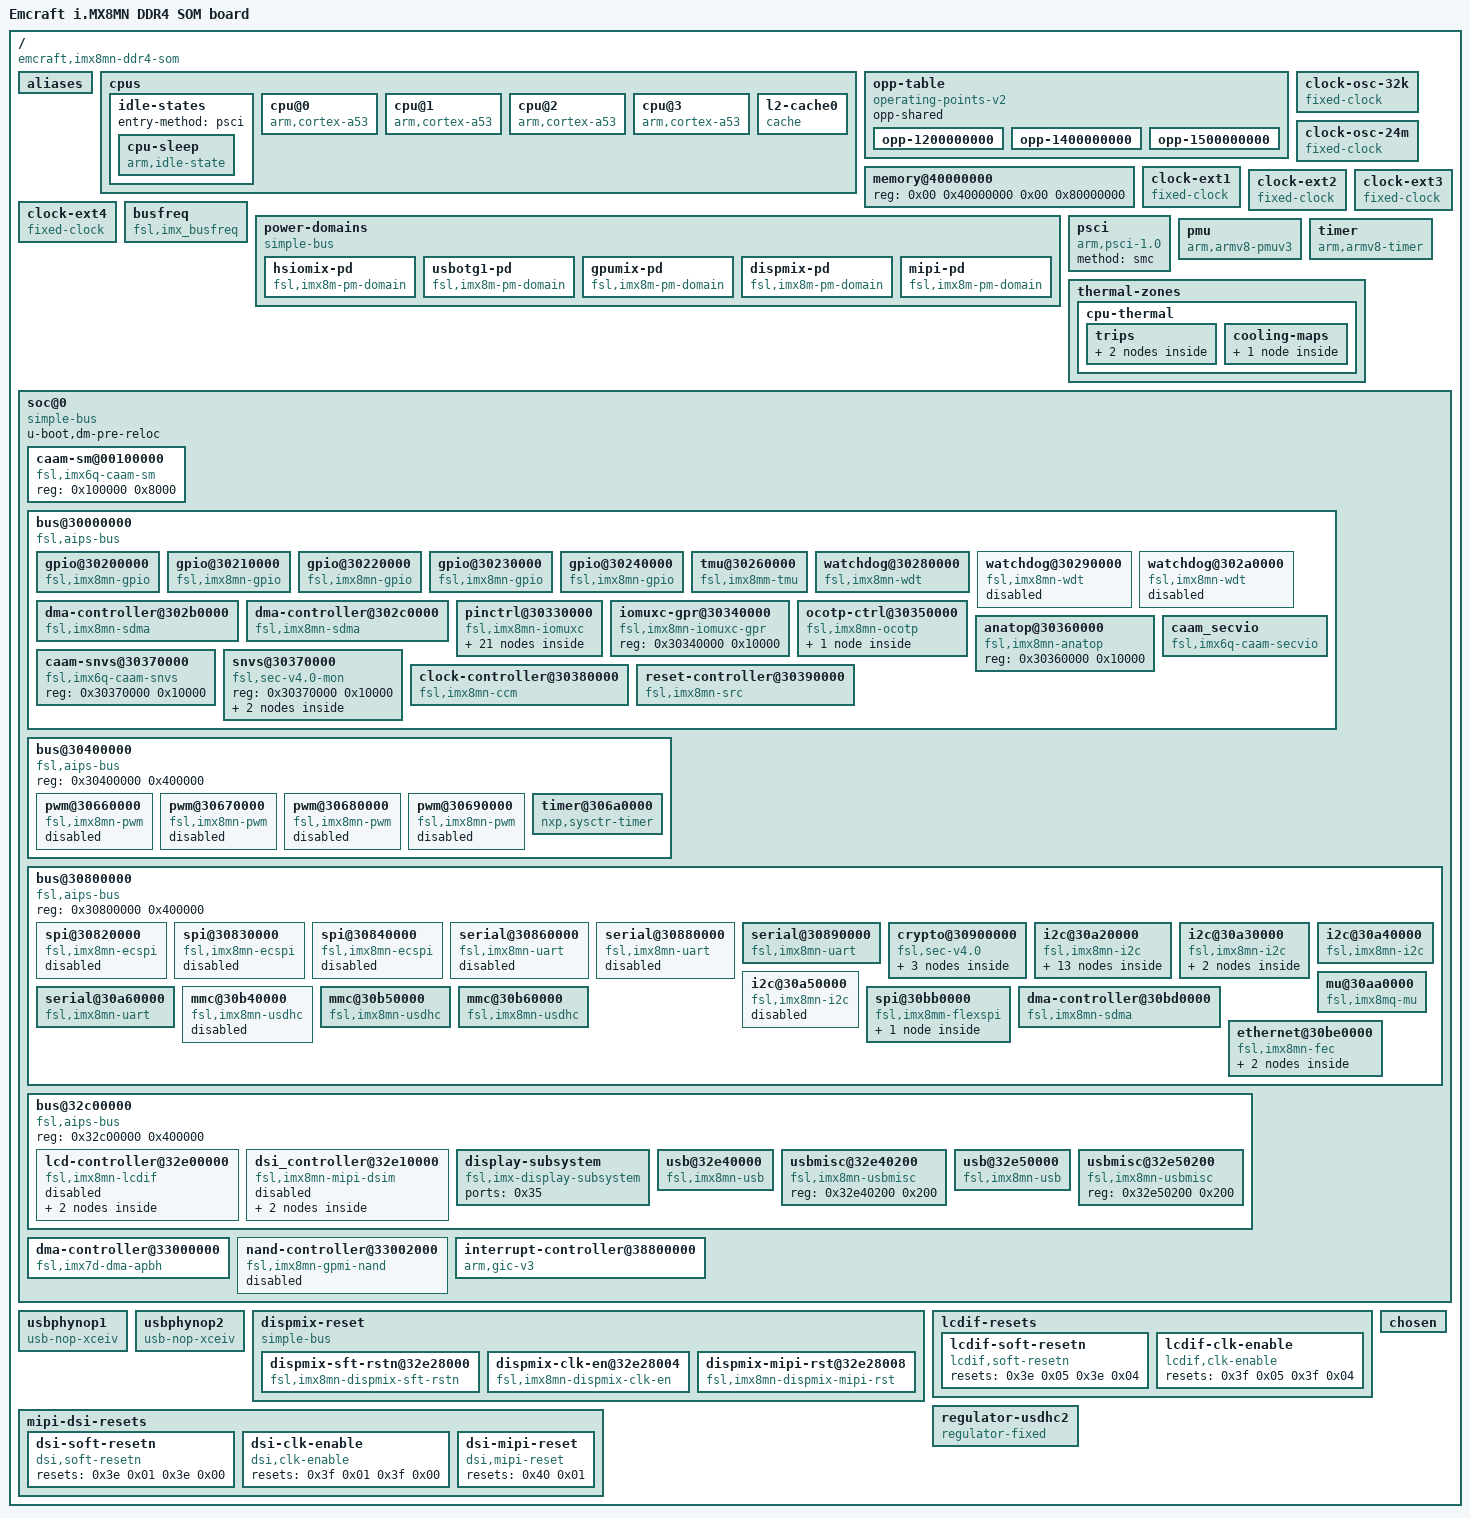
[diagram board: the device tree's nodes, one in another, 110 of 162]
/dts-v1/;

/ {
	compatible = "emcraft,imx8mn-ddr4-som\0fsl,imx8mn";
	interrupt-parent = <0x01>;
	#address-cells = <0x02>;
	#size-cells = <0x02>;
	model = "Emcraft i.MX8MN DDR4 SOM board";

	aliases {
		ethernet0 = "/soc@0/bus@30800000/ethernet@30be0000";
		gpio0 = "/soc@0/bus@30000000/gpio@30200000";
		gpio1 = "/soc@0/bus@30000000/gpio@30210000";
		gpio2 = "/soc@0/bus@30000000/gpio@30220000";
		gpio3 = "/soc@0/bus@30000000/gpio@30230000";
		gpio4 = "/soc@0/bus@30000000/gpio@30240000";
		i2c0 = "/soc@0/bus@30800000/i2c@30a20000";
		i2c1 = "/soc@0/bus@30800000/i2c@30a30000";
		i2c2 = "/soc@0/bus@30800000/i2c@30a40000";
		i2c3 = "/soc@0/bus@30800000/i2c@30a50000";
		mmc0 = "/soc@0/bus@30800000/mmc@30b40000";
		mmc1 = "/soc@0/bus@30800000/mmc@30b50000";
		mmc2 = "/soc@0/bus@30800000/mmc@30b60000";
		serial0 = "/soc@0/bus@30800000/serial@30860000";
		serial1 = "/soc@0/bus@30800000/serial@30890000";
		serial2 = "/soc@0/bus@30800000/serial@30880000";
		serial3 = "/soc@0/bus@30800000/serial@30a60000";
		spi0 = "/soc@0/bus@30800000/spi@30bb0000";
		usb0 = "/soc@0/bus@32c00000/usb@32e40000";
		usb1 = "/soc@0/bus@32c00000/usb@32e50000";
		video0 = "/soc@0/bus@32c00000/lcd-controller@32e00000";
	};

	cpus {
		#address-cells = <0x01>;
		#size-cells = <0x00>;

		idle-states {
			entry-method = "psci";

			cpu-sleep {
				compatible = "arm,idle-state";
				arm,psci-suspend-param = <0x10033>;
				local-timer-stop;
				entry-latency-us = <0x3e8>;
				exit-latency-us = <0x2bc>;
				min-residency-us = <0xa8c>;
				wakeup-latency-us = <0x5dc>;
				phandle = <0x06>;
			};
		};

		cpu@0 {
			device_type = "cpu";
			compatible = "arm,cortex-a53";
			reg = <0x00>;
			clock-latency = <0xee6c>;
			clocks = <0x02 0xbf>;
			enable-method = "psci";
			next-level-cache = <0x03>;
			operating-points-v2 = <0x04>;
			nvmem-cells = <0x05>;
			nvmem-cell-names = "speed_grade";
			cpu-idle-states = <0x06>;
			#cooling-cells = <0x02>;
			phandle = <0x09>;
		};

		cpu@1 {
			device_type = "cpu";
			compatible = "arm,cortex-a53";
			reg = <0x01>;
			clock-latency = <0xee6c>;
			clocks = <0x02 0xbf>;
			enable-method = "psci";
			next-level-cache = <0x03>;
			operating-points-v2 = <0x04>;
			cpu-idle-states = <0x06>;
			#cooling-cells = <0x02>;
			phandle = <0x0a>;
		};

		cpu@2 {
			device_type = "cpu";
			compatible = "arm,cortex-a53";
			reg = <0x02>;
			clock-latency = <0xee6c>;
			clocks = <0x02 0xbf>;
			enable-method = "psci";
			next-level-cache = <0x03>;
			operating-points-v2 = <0x04>;
			cpu-idle-states = <0x06>;
			#cooling-cells = <0x02>;
			phandle = <0x0b>;
		};

		cpu@3 {
			device_type = "cpu";
			compatible = "arm,cortex-a53";
			reg = <0x03>;
			clock-latency = <0xee6c>;
			clocks = <0x02 0xbf>;
			enable-method = "psci";
			next-level-cache = <0x03>;
			operating-points-v2 = <0x04>;
			cpu-idle-states = <0x06>;
			#cooling-cells = <0x02>;
			phandle = <0x0c>;
		};

		l2-cache0 {
			compatible = "cache";
			phandle = <0x03>;
		};
	};

	opp-table {
		compatible = "operating-points-v2";
		opp-shared;
		phandle = <0x04>;

		opp-1200000000 {
			opp-hz = <0x00 0x47868c00>;
			opp-microvolt = <0xcf850>;
			opp-supported-hw = <0xb00 0x07>;
			clock-latency-ns = <0x249f0>;
			opp-suspend;
		};

		opp-1400000000 {
			opp-hz = <0x00 0x53724e00>;
			opp-microvolt = <0xe7ef0>;
			opp-supported-hw = <0x300 0x07>;
			clock-latency-ns = <0x249f0>;
			opp-suspend;
		};

		opp-1500000000 {
			opp-hz = <0x00 0x59682f00>;
			opp-microvolt = <0xf4240>;
			opp-supported-hw = <0x100 0x03>;
			clock-latency-ns = <0x249f0>;
			opp-suspend;
		};
	};

	memory@40000000 {
		device_type = "memory";
		reg = <0x00 0x40000000 0x00 0x80000000>;
	};

	clock-osc-32k {
		compatible = "fixed-clock";
		#clock-cells = <0x00>;
		clock-frequency = <0x8000>;
		clock-output-names = "osc_32k";
		phandle = <0x13>;
	};

	clock-osc-24m {
		compatible = "fixed-clock";
		#clock-cells = <0x00>;
		clock-frequency = <0x16e3600>;
		clock-output-names = "osc_24m";
		phandle = <0x14>;
	};

	clock-ext1 {
		compatible = "fixed-clock";
		#clock-cells = <0x00>;
		clock-frequency = <0x7ed6b40>;
		clock-output-names = "clk_ext1";
		phandle = <0x15>;
	};

	clock-ext2 {
		compatible = "fixed-clock";
		#clock-cells = <0x00>;
		clock-frequency = <0x7ed6b40>;
		clock-output-names = "clk_ext2";
		phandle = <0x16>;
	};

	clock-ext3 {
		compatible = "fixed-clock";
		#clock-cells = <0x00>;
		clock-frequency = <0x7ed6b40>;
		clock-output-names = "clk_ext3";
		phandle = <0x17>;
	};

	clock-ext4 {
		compatible = "fixed-clock";
		#clock-cells = <0x00>;
		clock-frequency = <0x7ed6b40>;
		clock-output-names = "clk_ext4";
		phandle = <0x18>;
	};

	busfreq {
		compatible = "fsl,imx_busfreq";
		clocks = <0x02 0x29 0x02 0x59 0x02 0x5a 0x02 0x5a 0x02 0x58 0x02 0x5b 0x02 0x30 0x02 0x32 0x02 0x3f 0x02 0x53 0x02 0x54 0x02 0x4b 0x02 0x02 0x02 0x38 0x02 0x15>;
		clock-names = "dram_pll\0dram_alt_src\0dram_apb_src\0dram_apb_pre_div\0dram_core\0dram_alt_root\0sys_pll1_40m\0sys_pll1_100m\0sys_pll2_333m\0noc_div\0ahb_div\0main_axi_src\0osc_24m\0sys_pll1_800m\0dram_pll_div";
	};

	power-domains {
		compatible = "simple-bus";

		hsiomix-pd {
			compatible = "fsl,imx8m-pm-domain";
			domain-index = <0x00>;
			#power-domain-cells = <0x00>;
			domain-name = "hsiomix";
			clocks = <0x02 0xad>;
			phandle = <0x07>;
		};

		usbotg1-pd {
			compatible = "fsl,imx8m-pm-domain";
			#power-domain-cells = <0x00>;
			domain-index = <0x02>;
			domain-name = "usb_otg1";
			parent-domains = <0x07>;
			phandle = <0x38>;
		};

		gpumix-pd {
			compatible = "fsl,imx8m-pm-domain";
			domain-index = <0x04>;
			#power-domain-cells = <0x00>;
			domain-name = "gpumix";
			clocks = <0x02 0xc1 0x02 0x4a 0x02 0xb3 0x02 0x52>;
		};

		dispmix-pd {
			compatible = "fsl,imx8m-pm-domain";
			domain-index = <0x09>;
			#power-domain-cells = <0x00>;
			domain-name = "dispmix";
			clocks = <0x02 0xb8 0x02 0xb9>;
			phandle = <0x08>;
		};

		mipi-pd {
			compatible = "fsl,imx8m-pm-domain";
			domain-index = <0x0a>;
			#power-domain-cells = <0x00>;
			domain-name = "mipi";
			parent-domains = <0x08>;
			phandle = <0x33>;
		};
	};

	psci {
		compatible = "arm,psci-1.0";
		method = "smc";
	};

	pmu {
		compatible = "arm,armv8-pmuv3";
		interrupts = <0x01 0x07 0x3f04>;
		interrupt-affinity = <0x09 0x0a 0x0b 0x0c>;
	};

	timer {
		compatible = "arm,armv8-timer";
		interrupts = <0x01 0x0d 0x3f08 0x01 0x0e 0x3f08 0x01 0x0b 0x3f08 0x01 0x0a 0x3f08>;
		clock-frequency = <0x7a1200>;
		arm,no-tick-in-suspend;
	};

	thermal-zones {

		cpu-thermal {
			polling-delay-passive = <0xfa>;
			polling-delay = <0x7d0>;
			thermal-sensors = <0x0d>;

			trips {

				trip0 {
					temperature = <0x14c08>;
					hysteresis = <0x7d0>;
					type = "passive";
					phandle = <0x0e>;
				};

				trip1 {
					temperature = <0x17318>;
					hysteresis = <0x7d0>;
					type = "critical";
				};
			};

			cooling-maps {

				map0 {
					trip = <0x0e>;
					cooling-device = <0x09 0xffffffff 0xffffffff 0x0a 0xffffffff 0xffffffff 0x0b 0xffffffff 0xffffffff 0x0c 0xffffffff 0xffffffff>;
				};
			};
		};
	};

	soc@0 {
		compatible = "simple-bus";
		#address-cells = <0x01>;
		#size-cells = <0x01>;
		ranges = <0x00 0x00 0x00 0x3e000000>;
		u-boot,dm-pre-reloc;

		caam-sm@00100000 {
			compatible = "fsl,imx6q-caam-sm";
			reg = <0x100000 0x8000>;
		};

		bus@30000000 {
			compatible = "fsl,aips-bus\0simple-bus";
			reg = <0x30000000 0x400000>;
			#address-cells = <0x01>;
			#size-cells = <0x01>;
			ranges;
			u-boot,dm-pre-reloc;

			gpio@30200000 {
				compatible = "fsl,imx8mn-gpio\0fsl,imx35-gpio";
				reg = <0x30200000 0x10000>;
				interrupts = <0x00 0x40 0x04 0x00 0x41 0x04>;
				clocks = <0x02 0x8c>;
				gpio-controller;
				#gpio-cells = <0x02>;
				interrupt-controller;
				#interrupt-cells = <0x02>;
				gpio-ranges = <0x0f 0x00 0x0a 0x1e>;
				u-boot,dm-pre-reloc;
				phandle = <0x1f>;
			};

			gpio@30210000 {
				compatible = "fsl,imx8mn-gpio\0fsl,imx35-gpio";
				reg = <0x30210000 0x10000>;
				interrupts = <0x00 0x42 0x04 0x00 0x43 0x04>;
				clocks = <0x02 0x8d>;
				gpio-controller;
				#gpio-cells = <0x02>;
				interrupt-controller;
				#interrupt-cells = <0x02>;
				gpio-ranges = <0x0f 0x00 0x28 0x15>;
				u-boot,dm-pre-reloc;
				phandle = <0x42>;
			};

			gpio@30220000 {
				compatible = "fsl,imx8mn-gpio\0fsl,imx35-gpio";
				reg = <0x30220000 0x10000>;
				interrupts = <0x00 0x44 0x04 0x00 0x45 0x04>;
				clocks = <0x02 0x8e>;
				gpio-controller;
				#gpio-cells = <0x02>;
				interrupt-controller;
				#interrupt-cells = <0x02>;
				gpio-ranges = <0x0f 0x00 0x3d 0x1a>;
				u-boot,dm-pre-reloc;
			};

			gpio@30230000 {
				compatible = "fsl,imx8mn-gpio\0fsl,imx35-gpio";
				reg = <0x30230000 0x10000>;
				interrupts = <0x00 0x46 0x04 0x00 0x47 0x04>;
				clocks = <0x02 0x8f>;
				gpio-controller;
				#gpio-cells = <0x02>;
				interrupt-controller;
				#interrupt-cells = <0x02>;
				gpio-ranges = <0x0f 0x15 0x6c 0x0b>;
				u-boot,dm-pre-reloc;
			};

			gpio@30240000 {
				compatible = "fsl,imx8mn-gpio\0fsl,imx35-gpio";
				reg = <0x30240000 0x10000>;
				interrupts = <0x00 0x48 0x04 0x00 0x49 0x04>;
				clocks = <0x02 0x90>;
				gpio-controller;
				#gpio-cells = <0x02>;
				interrupt-controller;
				#interrupt-cells = <0x02>;
				gpio-ranges = <0x0f 0x00 0x77 0x1e>;
				u-boot,dm-pre-reloc;
				phandle = <0x1d>;
			};

			tmu@30260000 {
				compatible = "fsl,imx8mm-tmu";
				reg = <0x30260000 0x10000>;
				clocks = <0x02 0xbe>;
				u-boot,dm-pre-reloc;
				#thermal-sensor-cells = <0x00>;
				phandle = <0x0d>;
			};

			watchdog@30280000 {
				compatible = "fsl,imx8mn-wdt\0fsl,imx21-wdt";
				reg = <0x30280000 0x10000>;
				interrupts = <0x00 0x4e 0x04>;
				clocks = <0x02 0xb0>;
				status = "okay";
				pinctrl-names = "default";
				pinctrl-0 = <0x10>;
				fsl,ext-reset-output;
			};

			watchdog@30290000 {
				compatible = "fsl,imx8mn-wdt\0fsl,imx21-wdt";
				reg = <0x30290000 0x10000>;
				interrupts = <0x00 0x4f 0x04>;
				clocks = <0x02 0xb1>;
				status = "disabled";
			};

			watchdog@302a0000 {
				compatible = "fsl,imx8mn-wdt\0fsl,imx21-wdt";
				reg = <0x302a0000 0x10000>;
				interrupts = <0x00 0x0a 0x04>;
				clocks = <0x02 0xb2>;
				status = "disabled";
			};

			dma-controller@302b0000 {
				compatible = "fsl,imx8mn-sdma\0fsl,imx8mq-sdma\0fsl,imx7d-sdma";
				reg = <0x302b0000 0x10000>;
				interrupts = <0x00 0x22 0x04>;
				clocks = <0x02 0xbd 0x02 0xbd>;
				clock-names = "ipg\0ahb";
				#dma-cells = <0x03>;
				fsl,sdma-ram-script-name = "imx/sdma/sdma-imx7d.bin";
			};

			dma-controller@302c0000 {
				compatible = "fsl,imx8mn-sdma\0fsl,imx8mq-sdma\0fsl,imx7d-sdma";
				reg = <0x302c0000 0x10000>;
				interrupts = <0x00 0x67 0x04>;
				clocks = <0x02 0xa8 0x02 0xa8>;
				clock-names = "ipg\0ahb";
				#dma-cells = <0x03>;
				fsl,sdma-ram-script-name = "imx/sdma/sdma-imx7d.bin";
			};

			pinctrl@30330000 {
				compatible = "fsl,imx8mn-iomuxc";
				reg = <0x30330000 0x10000>;
				pinctrl-names = "default";
				pinctrl-0 = <0x11>;
				phandle = <0x0f>;

				imx8mn-evk {

					hoggrp-1 {
						fsl,pins = <0x48 0x2b0 0x00 0x00 0x00 0x16>;
						phandle = <0x11>;
					};

					fec1grp {
						fsl,pins = <0x68 0x2d0 0x00 0x00 0x00 0x03 0x6c 0x2d4 0x4c0 0x00 0x01 0x03 0x70 0x2d8 0x00 0x00 0x00 0x1f 0x74 0x2dc 0x00 0x00 0x00 0x1f 0x78 0x2e0 0x00 0x00 0x00 0x1f 0x7c 0x2e4 0x00 0x00 0x00 0x1f 0x9c 0x304 0x00 0x00 0x00 0x91 0x98 0x300 0x00 0x00 0x00 0x91 0x94 0x2fc 0x554 0x00 0x00 0x91 0x90 0x2f8 0x57c 0x00 0x00 0x91 0x84 0x2ec 0x00 0x00 0x00 0x1f 0x8c 0x2f4 0x00 0x00 0x00 0x91 0x88 0x2f0 0x574 0x00 0x00 0x91 0x80 0x2e8 0x00 0x00 0x00 0x1f 0x1b4 0x41c 0x00 0x05 0x00 0x19>;
						phandle = <0x2e>;
					};

					flexspi0grp {
						fsl,pins = <0xf4 0x35c 0x00 0x01 0x00 0x1c4 0xf8 0x360 0x00 0x01 0x00 0x84 0x10c 0x374 0x00 0x01 0x00 0x84 0x110 0x378 0x00 0x01 0x00 0x84 0x114 0x37c 0x00 0x01 0x00 0x84 0x118 0x380 0x00 0x01 0x00 0x84>;
						phandle = <0x2c>;
					};

					i2c1grp {
						fsl,pins = <0x214 0x47c 0x55c 0x00 0x00 0x400001c3 0x218 0x480 0x56c 0x00 0x00 0x400001c3>;
						phandle = <0x1b>;
					};

					i2c2grp {
						fsl,pins = <0x21c 0x484 0x5d0 0x00 0x00 0x400001c3 0x220 0x488 0x560 0x00 0x00 0x400001c3>;
						phandle = <0x20>;
					};

					i2c3grp {
						fsl,pins = <0x224 0x48c 0x588 0x00 0x00 0x400001c3 0x228 0x490 0x5bc 0x00 0x00 0x400001c3>;
						phandle = <0x22>;
					};

					i2c1grp-gpio {
						fsl,pins = <0x214 0x47c 0x00 0x05 0x00 0x1c3 0x218 0x480 0x00 0x05 0x00 0x1c3>;
						phandle = <0x1c>;
					};

					i2c2grp-gpio {
						fsl,pins = <0x21c 0x484 0x00 0x05 0x00 0x1c3 0x220 0x488 0x00 0x05 0x00 0x1c3>;
						phandle = <0x21>;
					};

					i2c3grp-gpio {
						fsl,pins = <0x224 0x48c 0x00 0x05 0x00 0x1c3 0x228 0x490 0x00 0x05 0x00 0x1c3>;
						phandle = <0x23>;
					};

					pmicirq {
						fsl,pins = <0x34 0x29c 0x00 0x00 0x00 0x41>;
						phandle = <0x1e>;
					};

					regusdhc2vmmc {
						fsl,pins = <0xec 0x354 0x00 0x05 0x00 0x41>;
						phandle = <0x41>;
					};

					uart2grp {
						fsl,pins = <0x23c 0x4a4 0x4fc 0x00 0x00 0x144 0x240 0x4a8 0x00 0x00 0x00 0x144>;
						phandle = <0x1a>;
					};

					usdhc2grpgpio {
						fsl,pins = <0x64 0x2cc 0x00 0x00 0x00 0x1c4>;
						phandle = <0x25>;
					};

					usdhc2grp {
						fsl,pins = <0xd4 0x33c 0x00 0x00 0x00 0x190 0xd8 0x340 0x00 0x00 0x00 0x1d0 0xdc 0x344 0x00 0x00 0x00 0x1d0 0xe0 0x348 0x00 0x00 0x00 0x1d0 0xe4 0x34c 0x00 0x00 0x00 0x1d0 0xe8 0x350 0x00 0x00 0x00 0x1d0 0x38 0x2a0 0x00 0x01 0x00 0x1d0>;
						phandle = <0x24>;
					};

					usdhc2grp100mhz {
						fsl,pins = <0xd4 0x33c 0x00 0x00 0x00 0x194 0xd8 0x340 0x00 0x00 0x00 0x1d4 0xdc 0x344 0x00 0x00 0x00 0x1d4 0xe0 0x348 0x00 0x00 0x00 0x1d4 0xe4 0x34c 0x00 0x00 0x00 0x1d4 0xe8 0x350 0x00 0x00 0x00 0x1d4 0x38 0x2a0 0x00 0x01 0x00 0x1d0>;
						phandle = <0x26>;
					};

					usdhc2grp200mhz {
						fsl,pins = <0xd4 0x33c 0x00 0x00 0x00 0x196 0xd8 0x340 0x00 0x00 0x00 0x1d6 0xdc 0x344 0x00 0x00 0x00 0x1d6 0xe0 0x348 0x00 0x00 0x00 0x1d6 0xe4 0x34c 0x00 0x00 0x00 0x1d6 0xe8 0x350 0x00 0x00 0x00 0x1d6 0x38 0x2a0 0x00 0x01 0x00 0x1d0>;
						phandle = <0x27>;
					};

					usdhc3grp {
						fsl,pins = <0x138 0x3a0 0x5a0 0x02 0x00 0x40000190 0x13c 0x3a4 0x5dc 0x02 0x00 0x1d0 0x11c 0x384 0x5b4 0x02 0x00 0x1d0 0x120 0x388 0x5b0 0x02 0x00 0x1d0 0x124 0x38c 0x5e4 0x02 0x00 0x1d0 0x128 0x390 0x5e0 0x02 0x00 0x1d0 0x130 0x398 0x558 0x02 0x00 0x1d0 0x100 0x368 0x550 0x02 0x00 0x1d0 0x104 0x36c 0x584 0x02 0x00 0x1d0 0x108 0x370 0x54c 0x02 0x00 0x1d0 0xfc 0x364 0x59c 0x02 0x00 0x190>;
						phandle = <0x29>;
					};

					usdhc3grp100mhz {
						fsl,pins = <0x138 0x3a0 0x5a0 0x02 0x00 0x40000194 0x13c 0x3a4 0x5dc 0x02 0x00 0x1d4 0x11c 0x384 0x5b4 0x02 0x00 0x1d4 0x120 0x388 0x5b0 0x02 0x00 0x1d4 0x124 0x38c 0x5e4 0x02 0x00 0x1d4 0x128 0x390 0x5e0 0x02 0x00 0x1d4 0x130 0x398 0x558 0x02 0x00 0x1d4 0x100 0x368 0x550 0x02 0x00 0x1d4 0x104 0x36c 0x584 0x02 0x00 0x1d4 0x108 0x370 0x54c 0x02 0x00 0x1d4 0xfc 0x364 0x59c 0x02 0x00 0x194>;
						phandle = <0x2a>;
					};

					usdhc3grp200mhz {
						fsl,pins = <0x138 0x3a0 0x5a0 0x02 0x00 0x40000196 0x13c 0x3a4 0x5dc 0x02 0x00 0x1d6 0x11c 0x384 0x5b4 0x02 0x00 0x1d6 0x120 0x388 0x5b0 0x02 0x00 0x1d6 0x124 0x38c 0x5e4 0x02 0x00 0x1d6 0x128 0x390 0x5e0 0x02 0x00 0x1d6 0x130 0x398 0x558 0x02 0x00 0x1d6 0x100 0x368 0x550 0x02 0x00 0x1d6 0x104 0x36c 0x584 0x02 0x00 0x1d6 0x108 0x370 0x54c 0x02 0x00 0x1d6 0xfc 0x364 0x59c 0x02 0x00 0x196>;
						phandle = <0x2b>;
					};

					wdoggrp {
						fsl,pins = <0x30 0x298 0x00 0x01 0x00 0xc6>;
						phandle = <0x10>;
					};
				};
			};

			iomuxc-gpr@30340000 {
				compatible = "fsl,imx8mn-iomuxc-gpr\0syscon";
				reg = <0x30340000 0x10000>;
				phandle = <0x2d>;
			};

			ocotp-ctrl@30350000 {
				compatible = "fsl,imx8mn-ocotp\0fsl,imx7d-ocotp\0syscon";
				reg = <0x30350000 0x10000>;
				clocks = <0x02 0x96>;
				#address-cells = <0x01>;
				#size-cells = <0x01>;

				speed-grade@10 {
					reg = <0x10 0x04>;
					phandle = <0x05>;
				};
			};

			anatop@30360000 {
				compatible = "fsl,imx8mn-anatop\0fsl,imx8mm-anatop\0syscon\0simple-bus";
				reg = <0x30360000 0x10000>;
			};

			caam_secvio {
				compatible = "fsl,imx6q-caam-secvio";
				interrupts = <0x00 0x14 0x04>;
				jtag-tamper = "disabled";
				watchdog-tamper = "enabled";
				internal-boot-tamper = "enabled";
				external-pin-tamper = "disabled";
			};

			caam-snvs@30370000 {
				compatible = "fsl,imx6q-caam-snvs";
				reg = <0x30370000 0x10000>;
			};

			snvs@30370000 {
				compatible = "fsl,sec-v4.0-mon\0syscon\0simple-mfd";
				reg = <0x30370000 0x10000>;
				phandle = <0x12>;

				snvs-rtc-lp {
					compatible = "fsl,sec-v4.0-mon-rtc-lp";
					regmap = <0x12>;
					offset = <0x34>;
					interrupts = <0x00 0x13 0x04 0x00 0x14 0x04>;
					clocks = <0x02 0xc4>;
					clock-names = "snvs-rtc";
				};

				snvs-powerkey {
					compatible = "fsl,sec-v4.0-pwrkey";
					regmap = <0x12>;
					interrupts = <0x00 0x04 0x04>;
					linux,keycode = <0x74>;
					wakeup-source;
					status = "okay";
				};
			};

			clock-controller@30380000 {
				compatible = "fsl,imx8mn-ccm";
				reg = <0x30380000 0x10000>;
				#clock-cells = <0x01>;
				clocks = <0x13 0x14 0x15 0x16 0x17 0x18>;
				clock-names = "osc_32k\0osc_24m\0clk_ext1\0clk_ext2\0clk_ext3\0clk_ext4";
				phandle = <0x02>;
			};

			reset-controller@30390000 {
				compatible = "fsl,imx8mn-src\0syscon";
				reg = <0x30390000 0x10000>;
				interrupts = <0x00 0x59 0x04>;
				#reset-cells = <0x01>;
			};
		};

		bus@30400000 {
			compatible = "fsl,aips-bus\0simple-bus";
			reg = <0x30400000 0x400000>;
			#address-cells = <0x01>;
			#size-cells = <0x01>;
			ranges;

			pwm@30660000 {
				compatible = "fsl,imx8mn-pwm\0fsl,imx27-pwm";
				reg = <0x30660000 0x10000>;
				interrupts = <0x00 0x51 0x04>;
				clocks = <0x02 0x97 0x02 0x97>;
				clock-names = "ipg\0per";
				#pwm-cells = <0x02>;
				status = "disabled";
			};

			pwm@30670000 {
				compatible = "fsl,imx8mn-pwm\0fsl,imx27-pwm";
				reg = <0x30670000 0x10000>;
				interrupts = <0x00 0x52 0x04>;
				clocks = <0x02 0x98 0x02 0x98>;
				clock-names = "ipg\0per";
				#pwm-cells = <0x02>;
				status = "disabled";
			};

			pwm@30680000 {
				compatible = "fsl,imx8mn-pwm\0fsl,imx27-pwm";
				reg = <0x30680000 0x10000>;
				interrupts = <0x00 0x53 0x04>;
				clocks = <0x02 0x99 0x02 0x99>;
				clock-names = "ipg\0per";
				#pwm-cells = <0x02>;
				status = "disabled";
			};

			pwm@30690000 {
				compatible = "fsl,imx8mn-pwm\0fsl,imx27-pwm";
				reg = <0x30690000 0x10000>;
				interrupts = <0x00 0x54 0x04>;
				clocks = <0x02 0x9a 0x02 0x9a>;
				clock-names = "ipg\0per";
				#pwm-cells = <0x02>;
				status = "disabled";
			};

			timer@306a0000 {
				compatible = "nxp,sysctr-timer";
				reg = <0x306a0000 0x20000>;
				interrupts = <0x00 0x2f 0x04>;
				clocks = <0x14>;
				clock-names = "per";
			};
		};

		bus@30800000 {
			compatible = "fsl,aips-bus\0simple-bus";
			reg = <0x30800000 0x400000>;
			#address-cells = <0x01>;
			#size-cells = <0x01>;
			ranges;

			spi@30820000 {
				compatible = "fsl,imx8mn-ecspi\0fsl,imx51-ecspi";
				#address-cells = <0x01>;
				#size-cells = <0x00>;
				reg = <0x30820000 0x10000>;
				interrupts = <0x00 0x1f 0x04>;
				clocks = <0x02 0x88 0x02 0x88>;
				clock-names = "ipg\0per";
				dmas = <0x19 0x00 0x07 0x01 0x19 0x01 0x07 0x02>;
				dma-names = "rx\0tx";
				status = "disabled";
			};

			spi@30830000 {
				compatible = "fsl,imx8mn-ecspi\0fsl,imx51-ecspi";
				#address-cells = <0x01>;
				#size-cells = <0x00>;
				reg = <0x30830000 0x10000>;
				interrupts = <0x00 0x20 0x04>;
				clocks = <0x02 0x89 0x02 0x89>;
				clock-names = "ipg\0per";
				dmas = <0x19 0x02 0x07 0x01 0x19 0x03 0x07 0x02>;
				dma-names = "rx\0tx";
				status = "disabled";
			};

			spi@30840000 {
				compatible = "fsl,imx8mn-ecspi\0fsl,imx51-ecspi";
				#address-cells = <0x01>;
				#size-cells = <0x00>;
				reg = <0x30840000 0x10000>;
				interrupts = <0x00 0x21 0x04>;
				clocks = <0x02 0x8a 0x02 0x8a>;
				clock-names = "ipg\0per";
				dmas = <0x19 0x04 0x07 0x01 0x19 0x05 0x07 0x02>;
				dma-names = "rx\0tx";
				status = "disabled";
			};

			serial@30860000 {
				compatible = "fsl,imx8mn-uart\0fsl,imx6q-uart";
				reg = <0x30860000 0x10000>;
				interrupts = <0x00 0x1a 0x04>;
				clocks = <0x02 0xa9 0x02 0xa9>;
				clock-names = "ipg\0per";
				dmas = <0x19 0x16 0x04 0x00 0x19 0x17 0x04 0x00>;
				dma-names = "rx\0tx";
				status = "disabled";
			};

			serial@30880000 {
				compatible = "fsl,imx8mn-uart\0fsl,imx6q-uart";
				reg = <0x30880000 0x10000>;
				interrupts = <0x00 0x1c 0x04>;
				clocks = <0x02 0xab 0x02 0xab>;
				clock-names = "ipg\0per";
				dmas = <0x19 0x1a 0x04 0x00 0x19 0x1b 0x04 0x00>;
				dma-names = "rx\0tx";
				status = "disabled";
			};

			serial@30890000 {
				compatible = "fsl,imx8mn-uart\0fsl,imx6q-uart";
				reg = <0x30890000 0x10000>;
				interrupts = <0x00 0x1b 0x04>;
				clocks = <0x02 0xaa 0x02 0xaa>;
				clock-names = "ipg\0per";
				status = "okay";
				pinctrl-names = "default";
				pinctrl-0 = <0x1a>;
			};

			crypto@30900000 {
				compatible = "fsl,sec-v4.0";
				#address-cells = <0x01>;
				#size-cells = <0x01>;
				reg = <0x30900000 0x40000>;
				ranges = <0x00 0x30900000 0x40000>;
				interrupts = <0x00 0x5b 0x04>;
				clocks = <0x02 0x54 0x02 0x56>;
				clock-names = "aclk\0ipg";

				jr@1000 {
					compatible = "fsl,sec-v4.0-job-ring";
					reg = <0x1000 0x1000>;
					interrupts = <0x00 0x69 0x04>;
				};

				jr@2000 {
					compatible = "fsl,sec-v4.0-job-ring";
					reg = <0x2000 0x1000>;
					interrupts = <0x00 0x6a 0x04>;
				};

				jr@3000 {
					compatible = "fsl,sec-v4.0-job-ring";
					reg = <0x3000 0x1000>;
					interrupts = <0x00 0x72 0x04>;
				};
			};

			i2c@30a20000 {
				compatible = "fsl,imx8mn-i2c\0fsl,imx21-i2c";
				#address-cells = <0x01>;
				#size-cells = <0x00>;
				reg = <0x30a20000 0x10000>;
				interrupts = <0x00 0x23 0x04>;
				clocks = <0x02 0x91>;
				status = "okay";
				clock-frequency = <0x61a80>;
				pinctrl-names = "default\0gpio";
				pinctrl-0 = <0x1b>;
				pinctrl-1 = <0x1c>;
				scl-gpios = <0x1d 0x0e 0x00>;
				sda-gpios = <0x1d 0x0f 0x00>;

				pca9450@25 {
					reg = <0x25>;
					compatible = "nxp,pca9450";
					pinctrl-0 = <0x1e>;
					gpio_intr = <0x1f 0x03 0x01>;

					regulators {
						#address-cells = <0x01>;
						#size-cells = <0x00>;
						pca9450,pmic-buck2-uses-i2c-dvs;
						pca9450,pmic-buck2-dvs-voltage = <0xe7ef0 0xcf850>;

						regulator@0 {
							reg = <0x00>;
							regulator-compatible = "buck1";
							regulator-min-microvolt = <0x927c0>;
							regulator-max-microvolt = <0x2160ec>;
							regulator-boot-on;
							regulator-always-on;
							regulator-ramp-delay = <0xc35>;
						};

						regulator@1 {
							reg = <0x01>;
							regulator-compatible = "buck2";
							regulator-min-microvolt = <0x927c0>;
							regulator-max-microvolt = <0x2160ec>;
							regulator-boot-on;
							regulator-always-on;
							regulator-ramp-delay = <0xc35>;
						};

						regulator@2 {
							reg = <0x02>;
							regulator-compatible = "buck3";
							regulator-min-microvolt = <0x927c0>;
							regulator-max-microvolt = <0x2160ec>;
							regulator-boot-on;
							regulator-always-on;
						};

						regulator@3 {
							reg = <0x03>;
							regulator-compatible = "buck4";
							regulator-min-microvolt = <0x927c0>;
							regulator-max-microvolt = <0x33e140>;
							regulator-boot-on;
							regulator-always-on;
						};

						regulator@4 {
							reg = <0x04>;
							regulator-compatible = "buck5";
							regulator-min-microvolt = <0x927c0>;
							regulator-max-microvolt = <0x33e140>;
							regulator-boot-on;
							regulator-always-on;
						};

						regulator@5 {
							reg = <0x05>;
							regulator-compatible = "buck6";
							regulator-min-microvolt = <0x927c0>;
							regulator-max-microvolt = <0x33e140>;
							regulator-boot-on;
							regulator-always-on;
						};

						regulator@6 {
							reg = <0x06>;
							regulator-compatible = "ldo1";
							regulator-min-microvolt = <0x186a00>;
							regulator-max-microvolt = <0x325aa0>;
							regulator-boot-on;
							regulator-always-on;
						};

						regulator@7 {
							reg = <0x07>;
							regulator-compatible = "ldo2";
							regulator-min-microvolt = "\0\f5";
							regulator-max-microvolt = <0x118c30>;
							regulator-boot-on;
							regulator-always-on;
						};

						regulator@8 {
							reg = <0x08>;
							regulator-compatible = "ldo3";
							regulator-min-microvolt = "\0\f5";
							regulator-max-microvolt = <0x325aa0>;
							regulator-boot-on;
							regulator-always-on;
						};

						regulator@9 {
							reg = <0x09>;
							regulator-compatible = "ldo4";
							regulator-min-microvolt = "\0\f5";
							regulator-max-microvolt = <0x325aa0>;
							regulator-boot-on;
							regulator-always-on;
						};

						regulator@10 {
							reg = <0x0a>;
							regulator-compatible = "ldo5";
							regulator-min-microvolt = <0x1b7740>;
							regulator-max-microvolt = <0x325aa0>;
						};
					};
				};
			};

			i2c@30a30000 {
				compatible = "fsl,imx8mn-i2c\0fsl,imx21-i2c";
				#address-cells = <0x01>;
				#size-cells = <0x00>;
				reg = <0x30a30000 0x10000>;
				interrupts = <0x00 0x24 0x04>;
				clocks = <0x02 0x92>;
				status = "okay";
				clock-frequency = <0x186a0>;
				pinctrl-names = "default\0gpio";
				pinctrl-0 = <0x20>;
				pinctrl-1 = <0x21>;
				scl-gpios = <0x1d 0x10 0x00>;
				sda-gpios = <0x1d 0x11 0x00>;

				ptn5110@50 {
					compatible = "usb,tcpci";
					reg = <0x50>;
					src-pdos = <0x380190c8>;
					snk-pdos = <0x380190c8 0x3802d0c8>;
					max-snk-mv = <0x2328>;
					max-snk-ma = <0x7d0>;
					op-snk-mw = <0x2328>;
					max-snk-mw = <0x4650>;
					port-type = "drp";
					default-role = "sink";
					phandle = <0x39>;
				};

				ptn5110@52 {
					compatible = "usb,tcpci";
					reg = <0x52>;
					src-pdos = <0x380190c8>;
					snk-pdos = <0x380190c8 0x3802d0c8>;
					max-snk-mv = <0x2328>;
					max-snk-ma = <0x7d0>;
					op-snk-mw = <0x2328>;
					max-snk-mw = <0x4650>;
					port-type = "drp";
					default-role = "sink";
					phandle = <0x3c>;
				};
			};

			i2c@30a40000 {
				#address-cells = <0x01>;
				#size-cells = <0x00>;
				compatible = "fsl,imx8mn-i2c\0fsl,imx21-i2c";
				reg = <0x30a40000 0x10000>;
				interrupts = <0x00 0x25 0x04>;
				clocks = <0x02 0x93>;
				status = "okay";
				clock-frequency = <0x186a0>;
				pinctrl-names = "default\0gpio";
				pinctrl-0 = <0x22>;
				pinctrl-1 = <0x23>;
				scl-gpios = <0x1d 0x12 0x00>;
				sda-gpios = <0x1d 0x13 0x00>;
			};

			i2c@30a50000 {
				compatible = "fsl,imx8mn-i2c\0fsl,imx21-i2c";
				#address-cells = <0x01>;
				#size-cells = <0x00>;
				reg = <0x30a50000 0x10000>;
				interrupts = <0x00 0x26 0x04>;
				clocks = <0x02 0x94>;
				status = "disabled";
			};

			serial@30a60000 {
				compatible = "fsl,imx8mn-uart\0fsl,imx6q-uart";
				reg = <0x30a60000 0x10000>;
				interrupts = <0x00 0x1d 0x04>;
				clocks = <0x02 0xac 0x02 0xac>;
				clock-names = "ipg\0per";
				dmas = <0x19 0x1c 0x04 0x00 0x19 0x1d 0x04 0x00>;
				dma-names = "rx\0tx";
				status = "okay";
			};

			mu@30aa0000 {
				compatible = "fsl,imx8mq-mu\0fsl,imx6sx-mu";
				reg = <0x30aa0000 0x10000>;
				interrupts = <0x00 0x58 0x04>;
				clocks = <0x02 0x95>;
				clock-names = "mu";
				#mbox-cells = <0x02>;
			};

			mmc@30b40000 {
				compatible = "fsl,imx8mn-usdhc\0fsl,imx7d-usdhc";
				reg = <0x30b40000 0x10000>;
				interrupts = <0x00 0x16 0x04>;
				clocks = <0x02 0x56 0x02 0x4d 0x02 0xae>;
				clock-names = "ipg\0ahb\0per";
				assigned-clocks = <0x02 0x67>;
				assigned-clock-rates = <0x17d78400>;
				fsl,tuning-start-tap = <0x14>;
				fsl,tuning-step = <0x02>;
				bus-width = <0x04>;
				status = "disabled";
			};

			mmc@30b50000 {
				compatible = "fsl,imx8mn-usdhc\0fsl,imx7d-usdhc";
				reg = <0x30b50000 0x10000>;
				interrupts = <0x00 0x17 0x04>;
				clocks = <0x02 0x56 0x02 0x4d 0x02 0xaf>;
				clock-names = "ipg\0ahb\0per";
				fsl,tuning-start-tap = <0x14>;
				fsl,tuning-step = <0x02>;
				bus-width = <0x04>;
				status = "okay";
				pinctrl-names = "default\0state_100mhz\0state_200mhz";
				pinctrl-0 = <0x24 0x25>;
				pinctrl-1 = <0x26 0x25>;
				pinctrl-2 = <0x27 0x25>;
				cd-gpios = <0x1f 0x0f 0x01>;
				vmmc-supply = <0x28>;
			};

			mmc@30b60000 {
				compatible = "fsl,imx8mn-usdhc\0fsl,imx7d-usdhc";
				reg = <0x30b60000 0x10000>;
				interrupts = <0x00 0x18 0x04>;
				clocks = <0x02 0x56 0x02 0x4d 0x02 0xbc>;
				clock-names = "ipg\0ahb\0per";
				assigned-clocks = <0x02 0xbc>;
				assigned-clock-rates = <0x17d78400>;
				fsl,tuning-start-tap = <0x14>;
				fsl,tuning-step = <0x02>;
				bus-width = <0x08>;
				status = "okay";
				pinctrl-names = "default\0state_100mhz\0state_200mhz";
				pinctrl-0 = <0x29>;
				pinctrl-1 = <0x2a>;
				pinctrl-2 = <0x2b>;
				non-removable;
			};

			spi@30bb0000 {
				#address-cells = <0x01>;
				#size-cells = <0x00>;
				compatible = "fsl,imx8mm-flexspi";
				reg = <0x30bb0000 0x10000 0x8000000 0x10000000>;
				reg-names = "FlexSPI\0FlexSPI-memory";
				interrupts = <0x00 0x6b 0x04>;
				clocks = <0x02 0x9b 0x02 0x9b>;
				clock-names = "fspi\0fspi_en";
				assigned-clock-rates = <0x4c4b400>;
				assigned-clocks = <0x02 0x66>;
				assigned-clock-parents = <0x02 0x37>;
				status = "okay";
				pinctrl-names = "default";
				pinctrl-0 = <0x2c>;

				mt25qu256aba@0 {
					reg = <0x00>;
					compatible = "jedec,spi-nor";
					spi-max-frequency = <0x4c4b400>;
					spi-tx-bus-width = <0x04>;
					spi-rx-bus-width = <0x04>;
				};
			};

			dma-controller@30bd0000 {
				compatible = "fsl,imx8mn-sdma\0fsl,imx8mq-sdma\0fsl,imx7d-sdma";
				reg = <0x30bd0000 0x10000>;
				interrupts = <0x00 0x02 0x04>;
				clocks = <0x02 0xa7 0x02 0x54>;
				clock-names = "ipg\0ahb";
				#dma-cells = <0x03>;
				fsl,sdma-ram-script-name = "imx/sdma/sdma-imx7d.bin";
				phandle = <0x19>;
			};

			ethernet@30be0000 {
				compatible = "fsl,imx8mn-fec\0fsl,imx8mq-fec\0fsl,imx6sx-fec";
				reg = <0x30be0000 0x10000>;
				interrupts = <0x00 0x76 0x04 0x00 0x77 0x04 0x00 0x78 0x04>;
				clocks = <0x02 0x8b 0x02 0x8b 0x02 0x63 0x02 0x62 0x02 0x64>;
				clock-names = "ipg\0ahb\0ptp\0enet_clk_ref\0enet_out";
				assigned-clocks = <0x02 0x4c 0x02 0x63 0x02 0x62 0x02 0x63>;
				assigned-clock-parents = <0x02 0x36 0x02 0x3a 0x02 0x3b>;
				assigned-clock-rates = <0x00 0x00 0x7735940 0x5f5e100>;
				fsl,num-tx-queues = <0x03>;
				fsl,num-rx-queues = <0x03>;
				stop-mode = <0x2d 0x10 0x03>;
				fsl,wakeup_irq = <0x02>;
				status = "okay";
				pinctrl-names = "default";
				pinctrl-0 = <0x2e>;
				phy-mode = "rgmii-id";
				phy-handle = <0x2f>;
				fsl,magic-packet;

				mdio {
					#address-cells = <0x01>;
					#size-cells = <0x00>;

					ethernet-phy@0 {
						compatible = "ethernet-phy-ieee802.3-c22";
						reg = <0x00>;
						at803x,led-act-blind-workaround;
						at803x,eee-disabled;
						at803x,vddio-1p8v;
						phandle = <0x2f>;
					};
				};
			};
		};

		bus@32c00000 {
			compatible = "fsl,aips-bus\0simple-bus";
			reg = <0x32c00000 0x400000>;
			#address-cells = <0x01>;
			#size-cells = <0x01>;
			ranges;

			lcd-controller@32e00000 {
				#address-cells = <0x01>;
				#size-cells = <0x00>;
				compatible = "fsl,imx8mn-lcdif";
				reg = <0x32e00000 0x10000>;
				clocks = <0x02 0xba 0x02 0xb8 0x02 0xb9>;
				clock-names = "pix\0disp-axi\0disp-apb";
				assigned-clocks = <0x02 0x5c 0x02 0x4e 0x02 0x4f>;
				assigned-clock-parents = <0x02 0x28 0x02 0x41 0x02 0x38>;
				assigned-clock-rates = <0x2367b880 0x1dcd6500 0xbebc200>;
				interrupts = <0x00 0x05 0x04>;
				resets = <0x30>;
				power-domains = <0x08>;
				status = "disabled";

				port@0 {
					reg = <0x00>;
					phandle = <0x35>;

					endpoint {
						remote-endpoint = <0x31>;
						phandle = <0x34>;
					};
				};
			};

			dsi_controller@32e10000 {
				#address-cells = <0x01>;
				#size-cells = <0x00>;
				compatible = "fsl,imx8mn-mipi-dsim";
				reg = <0x32e10000 0x400>;
				clocks = <0x02 0x7d 0x02 0x7e>;
				clock-names = "cfg\0pll-ref";
				assigned-clocks = <0x02 0x7d 0x02 0x7e>;
				assigned-clock-parents = <0x02 0x36 0x02 0x28>;
				assigned-clock-rates = <0xfdad680 0x2367b880>;
				interrupts = <0x00 0x12 0x04>;
				resets = <0x32>;
				power-domains = <0x33>;
				status = "disabled";

				port@0 {

					endpoint {
						remote-endpoint = <0x34>;
						phandle = <0x31>;
					};
				};
			};

			display-subsystem {
				compatible = "fsl,imx-display-subsystem";
				ports = <0x35>;
			};

			usb@32e40000 {
				compatible = "fsl,imx8mn-usb\0fsl,imx7d-usb\0fsl,imx27-usb";
				reg = <0x32e40000 0x200>;
				interrupts = <0x00 0x28 0x04>;
				clocks = <0x02 0xad>;
				clock-names = "usb1_ctrl_root_clk";
				assigned-clocks = <0x02 0x50 0x02 0x71>;
				assigned-clock-parents = <0x02 0x40 0x02 0x32>;
				fsl,usbphy = <0x36>;
				fsl,usbmisc = <0x37 0x00>;
				power-domains = <0x38>;
				status = "okay";
				extcon = <0x39>;
			};

			usbmisc@32e40200 {
				compatible = "fsl,imx8mn-usbmisc\0fsl,imx7d-usbmisc";
				#index-cells = <0x01>;
				reg = <0x32e40200 0x200>;
				phandle = <0x37>;
			};

			usb@32e50000 {
				compatible = "fsl,imx8mn-usb\0fsl,imx7d-usb\0fsl,imx27-usb";
				reg = <0x32e50000 0x200>;
				interrupts = <0x00 0x29 0x04>;
				clocks = <0x02 0xad>;
				clock-names = "usb1_ctrl_root_clk";
				assigned-clocks = <0x02 0x50 0x02 0x71>;
				assigned-clock-parents = <0x02 0x40 0x02 0x32>;
				fsl,usbphy = <0x3a>;
				fsl,usbmisc = <0x3b 0x00>;
				status = "okay";
				extcon = <0x3c>;
			};

			usbmisc@32e50200 {
				compatible = "fsl,imx8mn-usbmisc\0fsl,imx7d-usbmisc";
				#index-cells = <0x01>;
				reg = <0x32e50200 0x200>;
				phandle = <0x3b>;
			};
		};

		dma-controller@33000000 {
			compatible = "fsl,imx7d-dma-apbh\0fsl,imx28-dma-apbh";
			reg = <0x33000000 0x2000>;
			interrupts = <0x00 0x0c 0x04 0x00 0x0c 0x04 0x00 0x0c 0x04 0x00 0x0c 0x04>;
			interrupt-names = "gpmi0\0gpmi1\0gpmi2\0gpmi3";
			#dma-cells = <0x01>;
			dma-channels = <0x04>;
			clocks = <0x02 0xc0>;
			phandle = <0x3d>;
		};

		nand-controller@33002000 {
			compatible = "fsl,imx8mn-gpmi-nand\0fsl,imx7d-gpmi-nand";
			#address-cells = <0x01>;
			#size-cells = <0x01>;
			reg = <0x33002000 0x2000 0x33004000 0x4000>;
			reg-names = "gpmi-nand\0bch";
			interrupts = <0x00 0x0e 0x04>;
			interrupt-names = "bch";
			clocks = <0x02 0x9c 0x02 0xc0>;
			clock-names = "gpmi_io\0gpmi_bch_apb";
			dmas = <0x3d 0x00>;
			dma-names = "rx-tx";
			status = "disabled";
		};

		interrupt-controller@38800000 {
			compatible = "arm,gic-v3";
			reg = <0x38800000 0x10000 0x38880000 0xc0000>;
			#interrupt-cells = <0x03>;
			interrupt-controller;
			interrupts = <0x01 0x09 0x04>;
			phandle = <0x01>;
		};
	};

	usbphynop1 {
		compatible = "usb-nop-xceiv";
		clocks = <0x02 0x72>;
		assigned-clocks = <0x02 0x72>;
		assigned-clock-parents = <0x02 0x32>;
		clock-names = "main_clk";
		phandle = <0x36>;
	};

	usbphynop2 {
		compatible = "usb-nop-xceiv";
		clocks = <0x02 0x72>;
		assigned-clocks = <0x02 0x72>;
		assigned-clock-parents = <0x02 0x32>;
		clock-names = "main_clk";
		phandle = <0x3a>;
	};

	dispmix-reset {
		compatible = "simple-bus";
		#address-cells = <0x02>;
		#size-cells = <0x02>;
		ranges;

		dispmix-sft-rstn@32e28000 {
			compatible = "fsl,imx8mn-dispmix-sft-rstn";
			reg = <0x00 0x32e28000 0x00 0x04>;
			clocks = <0x02 0xb9>;
			clock-names = "disp_apb_root_clk";
			active_low;
			power-domains = <0x08>;
			#reset-cells = <0x01>;
			phandle = <0x3e>;
		};

		dispmix-clk-en@32e28004 {
			compatible = "fsl,imx8mn-dispmix-clk-en";
			reg = <0x00 0x32e28004 0x00 0x04>;
			clocks = <0x02 0xb9>;
			clock-names = "disp_apb_root_clk";
			power-domains = <0x08>;
			#reset-cells = <0x01>;
			phandle = <0x3f>;
		};

		dispmix-mipi-rst@32e28008 {
			compatible = "fsl,imx8mn-dispmix-mipi-rst";
			reg = <0x00 0x32e28008 0x00 0x04>;
			clocks = <0x02 0xb9>;
			clock-names = "disp_apb_root_clk";
			active_low;
			power-domains = <0x08>;
			#reset-cells = <0x01>;
			phandle = <0x40>;
		};
	};

	lcdif-resets {
		#address-cells = <0x01>;
		#size-cells = <0x00>;
		#reset-cells = <0x00>;
		phandle = <0x30>;

		lcdif-soft-resetn {
			compatible = "lcdif,soft-resetn";
			resets = <0x3e 0x05 0x3e 0x04>;
		};

		lcdif-clk-enable {
			compatible = "lcdif,clk-enable";
			resets = <0x3f 0x05 0x3f 0x04>;
		};
	};

	mipi-dsi-resets {
		#address-cells = <0x01>;
		#size-cells = <0x00>;
		#reset-cells = <0x00>;
		phandle = <0x32>;

		dsi-soft-resetn {
			compatible = "dsi,soft-resetn";
			resets = <0x3e 0x01 0x3e 0x00>;
		};

		dsi-clk-enable {
			compatible = "dsi,clk-enable";
			resets = <0x3f 0x01 0x3f 0x00>;
		};

		dsi-mipi-reset {
			compatible = "dsi,mipi-reset";
			resets = <0x40 0x01>;
		};
	};

	chosen {
		bootargs = "console=ttymxc1,115200 earlycon=ec_imx6q,0x30890000,115200";
		stdout-path = "/soc@0/bus@30800000/serial@30890000";
	};

	regulator-usdhc2 {
		compatible = "regulator-fixed";
		pinctrl-names = "default";
		pinctrl-0 = <0x41>;
		regulator-name = "VSD_3V3";
		regulator-min-microvolt = <0x325aa0>;
		regulator-max-microvolt = <0x325aa0>;
		gpio = <0x42 0x13 0x00>;
		enable-active-high;
		startup-delay-us = <0x64>;
		off-on-delay-us = <0x2ee0>;
		phandle = <0x28>;
	};
};
